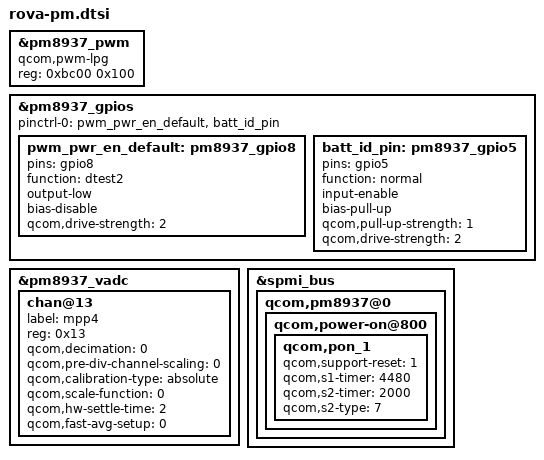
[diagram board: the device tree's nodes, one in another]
/* Copyright (c) 2015-2016, The Linux Foundation. All rights reserved.
 *
 * This program is free software; you can redistribute it and/or modify
 * it under the terms of the GNU General Public License version 2 and
 * only version 2 as published by the Free Software Foundation.
 *
 * This program is distributed in the hope that it will be useful,
 * but WITHOUT ANY WARRANTY; without even the implied warranty of
 * MERCHANTABILITY or FITNESS FOR A PARTICULAR PURPOSE.  See the
 * GNU General Public License for more details.
 */

&pm8937_pwm {
	status = "ok";
	compatible = "qcom,pwm-lpg";
	reg = <0xbc00 0x100>;
	reg-names = "lpg-base";
	#pwm-cells = <2>;
};

&pm8937_gpios {
	pinctrl-names = "default";
	pinctrl-0 = <&pwm_pwr_en_default &batt_id_pin>;
	pwm_pwr_en_default: pm8937_gpio8 {
		pins = "gpio8";
		function = "dtest2";
		output-low;
		bias-disable;
		qcom,drive-strength = <2>;
		status = "okay";
	};
	batt_id_pin: pm8937_gpio5 {
		pins = "gpio5";
		function = "normal";
		input-enable;
		bias-pull-up;
		qcom,pull-up-strength = <1>;
		qcom,drive-strength = <2>;
		status = "okay";
	};
};

&pm8937_vadc {
	chan@13 {
		label = "mpp4";
		reg = <0x13>;
		qcom,decimation = <0>;
		qcom,pre-div-channel-scaling = <0>;
		qcom,calibration-type = "absolute";
		qcom,scale-function = <0>;
		qcom,hw-settle-time = <2>;
		qcom,fast-avg-setup = <0>;
	};
};

&spmi_bus {
      qcom,pm8937@0 {
              qcom,power-on@800 {
	              qcom,pon_1 {
		              qcom,support-reset = <1>;
			      qcom,s1-timer = <4480>;
			      qcom,s2-timer = <2000>;
		              qcom,s2-type = <7>;
        	      };
	      };
       };
};

